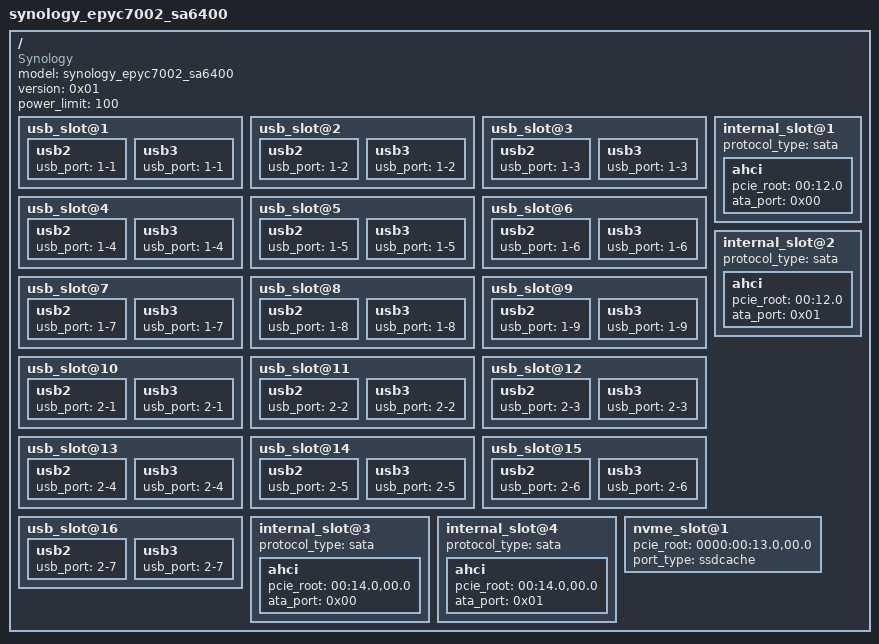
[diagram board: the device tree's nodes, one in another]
/dts-v1/;

/ {
	compatible = "Synology";
	model = "synology_epyc7002_sa6400";
	version = <0x01>;
	power_limit = "100";

	usb_slot@1 {

		usb2 {
			usb_port = "1-1";
		};

		usb3 {
			usb_port = "1-1";
		};
	};

	usb_slot@2 {

		usb2 {
			usb_port = "1-2";
		};

		usb3 {
			usb_port = "1-2";
		};
	};

	usb_slot@3 {

		usb2 {
			usb_port = "1-3";
		};

		usb3 {
			usb_port = "1-3";
		};
	};

	usb_slot@4 {

		usb2 {
			usb_port = "1-4";
		};

		usb3 {
			usb_port = "1-4";
		};
	};

	usb_slot@5 {

		usb2 {
			usb_port = "1-5";
		};

		usb3 {
			usb_port = "1-5";
		};
	};

	usb_slot@6 {

		usb2 {
			usb_port = "1-6";
		};

		usb3 {
			usb_port = "1-6";
		};
	};

	usb_slot@7 {

		usb2 {
			usb_port = "1-7";
		};

		usb3 {
			usb_port = "1-7";
		};
	};

	usb_slot@8 {

		usb2 {
			usb_port = "1-8";
		};

		usb3 {
			usb_port = "1-8";
		};
	};

	usb_slot@9 {

		usb2 {
			usb_port = "1-9";
		};

		usb3 {
			usb_port = "1-9";
		};
	};

	usb_slot@10 {

		usb2 {
			usb_port = "2-1";
		};

		usb3 {
			usb_port = "2-1";
		};
	};

	usb_slot@11 {

		usb2 {
			usb_port = "2-2";
		};

		usb3 {
			usb_port = "2-2";
		};
	};

	usb_slot@12 {

		usb2 {
			usb_port = "2-3";
		};

		usb3 {
			usb_port = "2-3";
		};
	};

	usb_slot@13 {

		usb2 {
			usb_port = "2-4";
		};

		usb3 {
			usb_port = "2-4";
		};
	};

	usb_slot@14 {

		usb2 {
			usb_port = "2-5";
		};

		usb3 {
			usb_port = "2-5";
		};
	};

	usb_slot@15 {

		usb2 {
			usb_port = "2-6";
		};

		usb3 {
			usb_port = "2-6";
		};
	};

	usb_slot@16 {

		usb2 {
			usb_port = "2-7";
		};

		usb3 {
			usb_port = "2-7";
		};
	};

	internal_slot@1 {
		protocol_type = "sata";

		ahci {
			pcie_root = "00:12.0";
			ata_port = <0x00>;
		};
	};
    internal_slot@2 {
		protocol_type = "sata";

		ahci {
			pcie_root = "00:12.0";
			ata_port = <0x01>;
		};
	};

	internal_slot@3 {
		protocol_type = "sata";

		ahci {
			pcie_root = "00:14.0,00.0";
			ata_port = <0x00>;
		};
	};
    
	internal_slot@4 {
		protocol_type = "sata";

		ahci {
			pcie_root = "00:14.0,00.0";
			ata_port = <0x01>;
		};
	};

	nvme_slot@1 {
		pcie_root = "0000:00:13.0,00.0";
		port_type = "ssdcache";
	};
};
